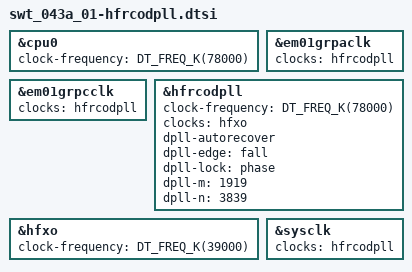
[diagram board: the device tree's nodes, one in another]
&cpu0 {
	clock-frequency = <DT_FREQ_K(78000)>;
};

&em01grpaclk {
	clocks = <&hfrcodpll>;
};

&em01grpcclk {
	clocks = <&hfrcodpll>;
};

&hfrcodpll {
	clock-frequency = <DT_FREQ_K(78000)>;
	clocks = <&hfxo>;
	dpll-autorecover;
	dpll-edge = "fall";
	dpll-lock = "phase";
	dpll-m = <1919>;
	dpll-n = <3839>;
};

&hfxo {
	status = "okay";
	clock-frequency = <DT_FREQ_K(39000)>;
};

&sysclk {
	clocks = <&hfrcodpll>;
};
